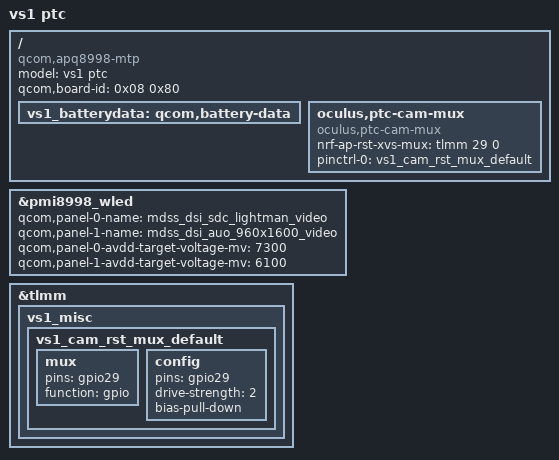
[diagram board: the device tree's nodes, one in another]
/* Copyright (c) 2016, The Linux Foundation. All rights reserved.
 *
 * This program is free software; you can redistribute it and/or modify
 * it under the terms of the GNU General Public License version 2 and
 * only version 2 as published by the Free Software Foundation.
 *
 * This program is distributed in the hope that it will be useful,
 * but WITHOUT ANY WARRANTY; without even the implied warranty of
 * MERCHANTABILITY or FITNESS FOR A PARTICULAR PURPOSE.  See the
 * GNU General Public License for more details.
 */


/dts-v1/;

#include "vs1-evt.dtsi"
#include "vs1-camera-ptc.dtsi"

/ {
	model = "vs1 ptc";
	compatible = "qcom,apq8998-mtp", "qcom,apq8998", "qcom,mtp";
	qcom,board-id = <0x08 0x80>;

	vs1_batterydata: qcom,battery-data {
		#include "3313509_Pegatron_VS1scud_4000mAh_averaged_MasterSlave_May15th2018_PMI8998GUI20058.dtsi"
	};

	oculus,ptc-cam-mux {
		compatible = "oculus,ptc-cam-mux";
		pinctrl-names = "ptc_defaults";
		nrf-ap-rst-xvs-mux = <&tlmm 29 0>;
		pinctrl-0 = <&vs1_cam_rst_mux_default>;
	};
};

&pmi8998_wled {
	qcom,panel-0-name = "mdss_dsi_sdc_lightman_video";
	qcom,panel-1-name = "mdss_dsi_auo_960x1600_video";
	qcom,panel-0-avdd-target-voltage-mv = <7300>;
	qcom,panel-1-avdd-target-voltage-mv = <6100>;
};

&tlmm {
	vs1_misc {
		vs1_cam_rst_mux_default: vs1_cam_rst_mux_default {
			mux {
				pins = "gpio29";
				function = "gpio";
			};
			config {
				pins = "gpio29";
				drive-strength = <2>;
				bias-pull-down;
			};
		};
	};
};
